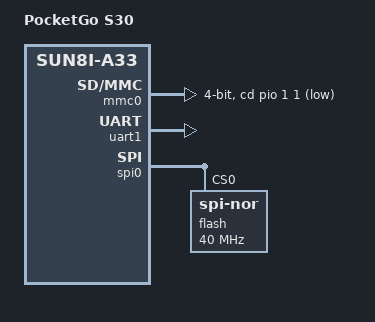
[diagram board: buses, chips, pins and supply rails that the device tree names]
// SPDX-License-Identifier: (GPL-2.0+ OR MIT)
/*
 * Minimal PocketGo S30 device tree for U-Boot: console, SD card and boot
 * flash. Pin muxing for the console and SD card is done by U-Boot itself;
 * SPI0 needs its pinctrl reference (an SD card boot never muxed PC0-PC3).
 */

/dts-v1/;
#include "sun8i-a33.dtsi"

#include <dt-bindings/gpio/gpio.h>

/ {
	model = "PocketGo S30";
	compatible = "pocketgo,s30", "allwinner,sun8i-a33";

	aliases {
		mmc0 = &mmc0;
		serial0 = &uart1;
		spi0 = &spi0;
	};

	chosen {
		stdout-path = "serial0:115200n8";
	};
};

&mmc0 {
	bus-width = <4>;
	cd-gpios = <&pio 1 1 GPIO_ACTIVE_LOW>; /* PB1 */
	status = "okay";
};

&uart1 {
	status = "okay";
};

/*
 * Boot flash: Zbit ZB25VQ64, 8 MiB, on SPI0 (PC0-PC3). U-Boot's A23/A33
 * dtsi has the controller and pins (unlike Linux's), disabled.
 */
&spi0 {
	pinctrl-names = "default";
	pinctrl-0 = <&spi0_pc_pins>;
	status = "okay";

	flash@0 {
		compatible = "jedec,spi-nor";
		reg = <0>;
		spi-max-frequency = <40000000>;
	};
};
